AUTOSAR XML (schema 4-0-3)
package /ComponentTypes
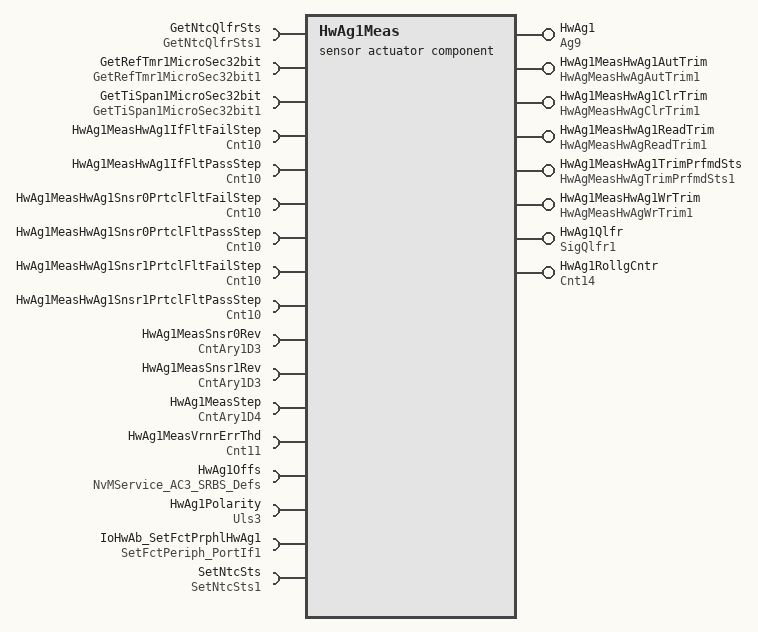
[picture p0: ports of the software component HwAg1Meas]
  sensor actuator sw component type HwAg1Meas
    8 x provide port:
      HwAg1: nonqueued-sender-com-spec{data-element=Val, init-value=0}, provided-interface=Ag9
      HwAg1MeasHwAg1AutTrim: server-com-spec{operation=Oper, queue-length=1}, provided-interface=HwAgMeasHwAgAutTrim1
      HwAg1MeasHwAg1ClrTrim: server-com-spec{operation=Oper, queue-length=1}, provided-interface=HwAgMeasHwAgClrTrim1
      HwAg1MeasHwAg1ReadTrim: server-com-spec{operation=Oper, queue-length=1}, provided-interface=HwAgMeasHwAgReadTrim1
      HwAg1MeasHwAg1TrimPrfmdSts: server-com-spec{operation=Oper, queue-length=1}, provided-interface=HwAgMeasHwAgTrimPrfmdSts1
      HwAg1MeasHwAg1WrTrim: server-com-spec{operation=Oper, queue-length=1}, provided-interface=HwAgMeasHwAgWrTrim1
      HwAg1Qlfr: nonqueued-sender-com-spec{data-element=Val, init-value=0}, provided-interface=SigQlfr1
      HwAg1RollgCntr: nonqueued-sender-com-spec{data-element=Val, init-value=0}, provided-interface=Cnt14
    17 x require port:
      GetNtcQlfrSts: required-interface=GetNtcQlfrSts1
      GetRefTmr1MicroSec32bit: required-interface=GetRefTmr1MicroSec32bit1
      GetTiSpan1MicroSec32bit: required-interface=GetTiSpan1MicroSec32bit1
      HwAg1MeasHwAg1IfFltFailStep: parameter-require-com-spec{init-value=2521, parameter=Val}, required-interface=Cnt10
      HwAg1MeasHwAg1IfFltPassStep: parameter-require-com-spec{init-value=1000, parameter=Val}, required-interface=Cnt10
      HwAg1MeasHwAg1Snsr0PrtclFltFailStep: parameter-require-com-spec{init-value=2521, parameter=Val}, required-interface=Cnt10
      HwAg1MeasHwAg1Snsr0PrtclFltPassStep: parameter-require-com-spec{init-value=1000, parameter=Val}, required-interface=Cnt10
      HwAg1MeasHwAg1Snsr1PrtclFltFailStep: parameter-require-com-spec{init-value=2521, parameter=Val}, required-interface=Cnt10
      HwAg1MeasHwAg1Snsr1PrtclFltPassStep: parameter-require-com-spec{init-value=1000, parameter=Val}, required-interface=Cnt10
      HwAg1MeasSnsr0Rev: parameter-require-com-spec{init-value=[0, 1, 1, 2, 2, 3, 3, 4, 4, 5, 5, 6, 6, 7, 7, 8, 8, 9, 9, 10, 10, 0], parameter=Ary1D}, required-interface=CntAry1D3
      HwAg1MeasSnsr1Rev: parameter-require-com-spec{init-value=[0, 0, 1, 1, 2, 2, 3, 3, 4, 4, 5, 5, 6, 6, 7, 7, 8, 8, 9, 9, 10, 10], parameter=Ary1D}, required-interface=CntAry1D3
      HwAg1MeasStep: parameter-require-com-spec{init-value=[0, -360, 36, -324, 72, -288, 108, -252, 144, -216, 180, -180, 216, -144, 252, -108, 288, -72, 324, -36, 360, -396], parameter=Ary1D}, required-interface=CntAry1D4
      HwAg1MeasVrnrErrThd: parameter-require-com-spec{init-value=8, parameter=Val}, required-interface=Cnt11
      HwAg1Offs: required-interface=NvMService_AC3_SRBS_Defs
      HwAg1Polarity: nonqueued-receiver-com-spec{data-element=Val, filter=data-filter-type=ALWAYS, init-value=1}, required-interface=Uls3
      IoHwAb_SetFctPrphlHwAg1: required-interface=SetFctPeriph_PortIf1
      SetNtcSts: required-interface=SetNtcSts1
    behavior HwAg1Meas_InternalBehavior: data-type-mapping=Nexteer
      ar-typed-per-instance-memorys:
        29 x data, all with sw-calibration-access=READ-ONLY:
          dHwAg1MeasSnsr0Abs: type=Cnt34
          dHwAg1MeasSnsr0CS: type=uint32
          dHwAg1MeasSnsr0FRXD: type=uint32
          dHwAg1MeasSnsr0Rel: type=Cnt32
          dHwAg1MeasSnsr1Abs: type=Cnt34
          dHwAg1MeasSnsr1CS: type=uint32
          dHwAg1MeasSnsr1FRXD: type=uint32
          dHwAg1MeasSnsr1Rel: type=Cnt32
          HwAg1InitStepSeqNrCmpl: type=Logl1
          HwAg1Offs: type=HwAgOffsRecAppl1
          HwAg1PrevHwAg1: type=Ag19
          HwAg1PrevRollCnt: type=Cnt19
          HwAg1PrevStepSeqNr: type=Cnt33
          HwAg1RawDataAvlStrtTi: type=uint32
          HwAg1Snsr0ComStsErrCntr: type=uint8
          HwAg1Snsr0IdErrCntr: type=uint8
          HwAg1Snsr0IntSnsrErrCntr: type=uint8
          HwAg1Snsr0NoMsgErrCntr: type=uint8
          HwAg1Snsr1ComStsErrCntr: type=uint8
          HwAg1Snsr1IdErrCntr: type=uint8
          HwAg1Snsr1IntSnsrErrCntr: type=uint8
          HwAg1Snsr1NoMsgErrCntr: type=uint8
          HwAg1SnsrTrigNr: type=uint8
          PrevHwAg1: type=float32
          PrevHwAg1Qlfr: type=SigQlfr1
          PrevHwAg1Snsr0Raw: type=uint16
          PrevHwAg1Snsr0TestOk: type=uint8
          PrevHwAg1Snsr1Raw: type=uint16
          PrevHwAg1Snsr1TestOk: type=uint8
      5 x operation invoked event:
        OIT_HwAg1MeasHwAg1AutTrim_Oper_HwAg1MeasHwAg1AutTrim_Oper: start-on-event=HwAg1MeasHwAg1AutTrim_Oper, operation=HwAg1MeasHwAg1AutTrim.Oper
        OIT_HwAg1MeasHwAg1ClrTrim_Oper_HwAg1MeasHwAg1ClrTrim_Oper: start-on-event=HwAg1MeasHwAg1ClrTrim_Oper, operation=HwAg1MeasHwAg1ClrTrim.Oper
        OIT_HwAg1MeasHwAg1ReadTrim_Oper_HwAg1MeasHwAg1ReadTrim_Oper: start-on-event=HwAg1MeasHwAg1ReadTrim_Oper, operation=HwAg1MeasHwAg1ReadTrim.Oper
        OIT_HwAg1MeasHwAg1TrimPrfmdSts_Oper_HwAg1MeasHwAg1TrimPrfmdSts_Oper: start-on-event=HwAg1MeasHwAg1TrimPrfmdSts_Oper, operation=HwAg1MeasHwAg1TrimPrfmdSts.Oper
        OIT_HwAg1MeasHwAg1WrTrim_Oper_HwAg1MeasHwAg1WrTrim_Oper: start-on-event=HwAg1MeasHwAg1WrTrim_Oper, operation=HwAg1MeasHwAg1WrTrim.Oper
      6 x timing event:
        HwAg0Meas_InitEvent: start-on-event=HwAg1MeasInit1, period=0
        TMT_HwAg0MeasPer{1..4}: start-on-event=HwAg1MeasPer{1..4}, period=0.002
        TMT_HwAg0MeasPer5: start-on-event=HwAg1MeasPer5, period=0.1
      explicit-inter-runnable-variables:
        4 x data, all with init-value=0:
          HwAg1Snsr0Raw: type=Cnt31
          HwAg1Snsr0TestOk: type=Cnt13
          HwAg1Snsr1Raw: type=Cnt31
          HwAg1Snsr1TestOk: type=Cnt13
      11 x runnable:
        HwAg1MeasHwAg1AutTrim_Oper
          sync call SC_HwAg1Offs_SetRamBlockStatus: operation=HwAg1Offs.SetRamBlockStatus, timeout=0
        HwAg1MeasHwAg1ClrTrim_Oper
          sync call SC_HwAg1Offs_SetRamBlockStatus: operation=HwAg1Offs.SetRamBlockStatus, timeout=0
        HwAg1MeasHwAg1ReadTrim_Oper
        HwAg1MeasHwAg1TrimPrfmdSts_Oper
        HwAg1MeasHwAg1WrTrim_Oper
          sync call SC_HwAg1Offs_SetRamBlockStatus: operation=HwAg1Offs.SetRamBlockStatus, timeout=0
        HwAg1MeasInit1
          sync call SC_GetRefTmr1MicroSec32bit_Oper: operation=GetRefTmr1MicroSec32bit.Oper, timeout=0
          sync call SC_GetTiSpan1MicroSec32bit_Oper: operation=GetTiSpan1MicroSec32bit.Oper, timeout=0
          sync call SC_IoHwAb_SetFctPrphlHwAg1_Oper: operation=IoHwAb_SetFctPrphlHwAg1.Oper, timeout=0
        HwAg1MeasPer1
          sync call SC_GetRefTmr1MicroSec32bit_Oper: operation=GetRefTmr1MicroSec32bit.Oper, timeout=0
          sync call SC_GetTiSpan1MicroSec32bit_Oper: operation=GetTiSpan1MicroSec32bit.Oper, timeout=0
        HwAg1MeasPer2
          sync call SC_GetRefTmr1MicroSec32bit_Oper: operation=GetRefTmr1MicroSec32bit.Oper, timeout=0
          sync call SC_GetTiSpan1MicroSec32bit_Oper: operation=GetTiSpan1MicroSec32bit.Oper, timeout=0
          sync call SC_SetNtcSts_Oper: operation=SetNtcSts.Oper, timeout=0
          written-local-variables:
            access WRITE_HwAg1Snsr0Raw: accessed-variable=HwAg1Snsr0Raw
            access WRITE_HwAg1Snsr0TestOk: accessed-variable=HwAg1Snsr0TestOk
        HwAg1MeasPer3
          sync call SC_GetRefTmr1MicroSec32bit_Oper: operation=GetRefTmr1MicroSec32bit.Oper, timeout=0
          sync call SC_GetTiSpan1MicroSec32bit_Oper: operation=GetTiSpan1MicroSec32bit.Oper, timeout=0
          sync call SC_SetNtcSts_Oper: operation=SetNtcSts.Oper, timeout=0
          written-local-variables:
            4 x access:
              WRITE_HwAg1Snsr0Raw: accessed-variable=HwAg1Snsr0Raw
              WRITE_HwAg1Snsr0TestOk: accessed-variable=HwAg1Snsr0TestOk
              WRITE_HwAg1Snsr1Raw: accessed-variable=HwAg1Snsr1Raw
              WRITE_HwAg1Snsr1TestOk: accessed-variable=HwAg1Snsr1TestOk
        HwAg1MeasPer4
          data-receive-point-by-arguments:
            access REC_HwAg1Polarity_Val: accessed-variable=HwAg1Polarity.Val
          data-send-points:
            access SEND_HwAg1_Val: accessed-variable=HwAg1.Val
            access SEND_HwAg1Qlfr_Val: accessed-variable=HwAg1Qlfr.Val
            access SEND_HwAg1RollgCntr_Val: accessed-variable=HwAg1RollgCntr.Val
          read-local-variables:
            4 x access:
              READ_HwAg1Snsr0Raw: accessed-variable=HwAg1Snsr0Raw
              READ_HwAg1Snsr0TestOk: accessed-variable=HwAg1Snsr0TestOk
              READ_HwAg1Snsr1Raw: accessed-variable=HwAg1Snsr1Raw
              READ_HwAg1Snsr1TestOk: accessed-variable=HwAg1Snsr1TestOk
          4 x sync call, all with timeout=0:
            SC_GetNtcQlfrSts_Oper: operation=GetNtcQlfrSts.Oper
            SC_GetRefTmr1MicroSec32bit_Oper: operation=GetRefTmr1MicroSec32bit.Oper
            SC_GetTiSpan1MicroSec32bit_Oper: operation=GetTiSpan1MicroSec32bit.Oper
            SC_SetNtcSts_Oper: operation=SetNtcSts.Oper
          written-local-variables:
            access WRITE_HwAg1Snsr1Raw: accessed-variable=HwAg1Snsr1Raw
            access WRITE_HwAg1Snsr1TestOk: accessed-variable=HwAg1Snsr1TestOk
        HwAg1MeasPer5
          data-receive-point-by-arguments:
            access REC_HwAg0Polarity_Val: accessed-variable=HwAg1Polarity.Val
          data-send-points:
            access SEND_HwAg0_Val: accessed-variable=HwAg1.Val
            access SEND_HwAg0Qlfr_Val: accessed-variable=HwAg1Qlfr.Val
            access SEND_HwAg0RollgCntr_Val: accessed-variable=HwAg1RollgCntr.Val
          read-local-variables:
            4 x access:
              READ_HwAg1Snsr0Raw: accessed-variable=HwAg1Snsr0Raw
              READ_HwAg1Snsr0TestOk: accessed-variable=HwAg1Snsr0TestOk
              READ_HwAg1Snsr1Raw: accessed-variable=HwAg1Snsr1Raw
              READ_HwAg1Snsr1TestOk: accessed-variable=HwAg1Snsr1TestOk
          sync call SC_GetNtcQlfrSts_Oper: operation=GetNtcQlfrSts.Oper, timeout=0
          sync call SC_SetNtcSts_Oper: operation=SetNtcSts.Oper, timeout=0
      swc service dependency NvmHwAg1Offs: assigned-datas=[{role=ramBlock, used-data-element=HwAg1Offs}, {role=defaultValue, used-parameter-element=HwAg1OffsDft}]
        assigned-ports:
          port-prototype=HwAg1Offs, role=NvMService_AC3_SRBS_Defs
          port-prototype=HwAg1Offs, role=NvMService_AC3_SRBS_Defs
        service-needs:
          nv block needs NvmHwAg1Offs: n-data-sets=0, readonly=false, reliability=ERROR-DETECTION, resistant-to-changed-sw=true, restore-at-start=true, store-at-shutdown=true, write-only-once=false, writing-frequency=0, writing-priority=LOW
      shared-parameters:
        parameter data prototype HwAg1OffsDft: sw-calibration-access=READ-WRITE, type=HwAgOffsRecAppl1, init-value=fields=[OffsTrimPrfmdSts:0, OffsTrim:0]
  swc implementation HwAg1Meas_Implementation: behavior=HwAg1Meas_InternalBehavior
    code-descriptors:
      code Default: artifact-descriptors=autosar-engineering-object={short-label=Default, category=SWSRC}
